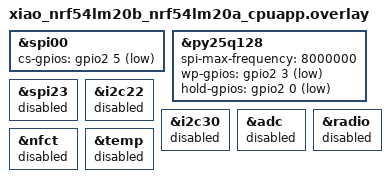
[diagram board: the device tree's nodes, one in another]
/* XIAO nRF54LM20B board overlay — shallow sleep demo.
 * Enable the on-board external SPI flash (PY25Q128HA) at a conservative 8 MHz
 * so the spi-nor driver probes it at boot (the board dtsi default of 133 MHz
 * makes the boot-time JEDEC/SFDP probe fail -> device not ready -> the flash
 * never enters DPD) and the demo can then suspend it into Deep Power-Down.
 * Disable unused peripherals to minimise idle current. &uart21 (the chosen
 * console) is kept enabled.
 */

&spi00 {
	status = "okay";
	cs-gpios = <&gpio2 5 GPIO_ACTIVE_LOW>;
};

&py25q128 {
	status = "okay";
	spi-max-frequency = <8000000>;
	wp-gpios = <&gpio2 3 GPIO_ACTIVE_LOW>;
	hold-gpios = <&gpio2 0 GPIO_ACTIVE_LOW>;
};

/* &uart21 is the chosen console (zephyr,console = &uart21); keep it enabled. */

&spi23 {
	status = "disabled";
};

&i2c22 {
	status = "disabled";
};

&i2c30 {
	status = "disabled";
};

&adc {
	status = "disabled";
};

&radio {
	status = "disabled";
};

&nfct {
	status = "disabled";
};

&temp {
	status = "disabled";
};
